VERSION "HIPBNYYYYYYYYYYYYYYYYYYYYYYYYYYYYYYYYYYYYY/4/%%%/4/'%**4YYY///"

NS_ :

BS_:

BU_: SpeedNode RFNode DisplayNode BMS MPPT

BO_ 3221225472 VECTOR__INDEPENDENT_SIG_MSG: 0 Vector__XXX
 SG_ State : 0|1@0+ (1,0) [0|0] "" Vector__XXX

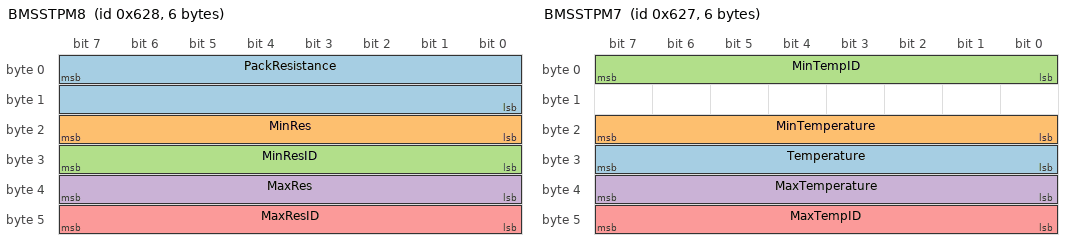
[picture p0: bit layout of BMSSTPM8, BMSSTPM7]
BO_ 1576 BMSSTPM8: 6 BMS
 SG_ PackResistance : 7|16@0+ (1,0) [0|0] "" Vector__XXX
 SG_ MinRes : 23|8@0+ (1,0) [0|0] "" Vector__XXX
 SG_ MinResID : 31|8@0+ (1,0) [0|0] "" Vector__XXX
 SG_ MaxRes : 39|8@0+ (1,0) [0|0] "" Vector__XXX
 SG_ MaxResID : 47|8@0+ (1,0) [0|0] "" Vector__XXX

BO_ 1575 BMSSTPM7: 6 BMS
 SG_ Temperature : 31|8@0+ (1,0) [0|0] "" Vector__XXX
 SG_ MinTemperature : 23|8@0+ (1,0) [0|0] "" Vector__XXX
 SG_ MinTempID : 7|8@0+ (1,0) [0|0] "" Vector__XXX
 SG_ MaxTemperature : 39|8@0+ (1,0) [0|0] "" Vector__XXX
 SG_ MaxTempID : 47|8@0+ (1,0) [0|0] "" Vector__XXX

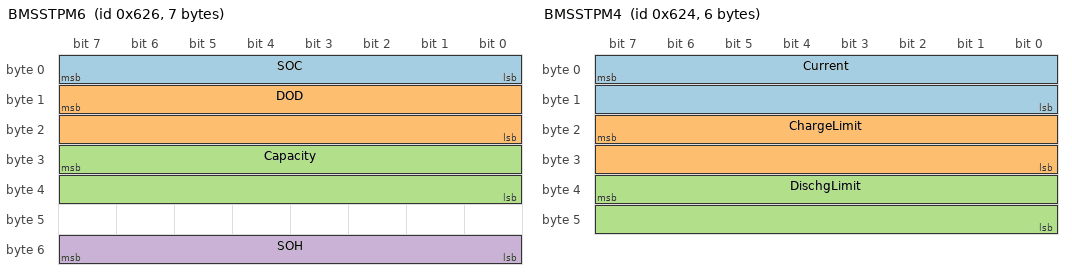
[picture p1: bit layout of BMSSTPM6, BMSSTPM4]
BO_ 1574 BMSSTPM6: 7 BMS
 SG_ SOC : 7|8@0+ (1,0) [0|0] "" Vector__XXX
 SG_ DOD : 15|16@0+ (1,0) [0|0] "" Vector__XXX
 SG_ Capacity : 31|16@0+ (1,0) [0|0] "" Vector__XXX
 SG_ SOH : 55|8@0+ (1,0) [0|0] "" Vector__XXX

BO_ 1573 BMSSTPM5: 8 BMS
 SG_ BattEnergyIn : 7|32@0+ (1,0) [0|0] "" Vector__XXX
 SG_ BattEnergyOut : 39|32@0+ (1,0) [0|0] "" Vector__XXX

BO_ 1572 BMSSTPM4: 6 BMS
 SG_ Current : 7|16@0+ (1,0) [0|0] "" Vector__XXX
 SG_ ChargeLimit : 23|16@0+ (1,0) [0|0] "" Vector__XXX
 SG_ DischgLimit : 39|16@0+ (1,0) [0|0] "" Vector__XXX

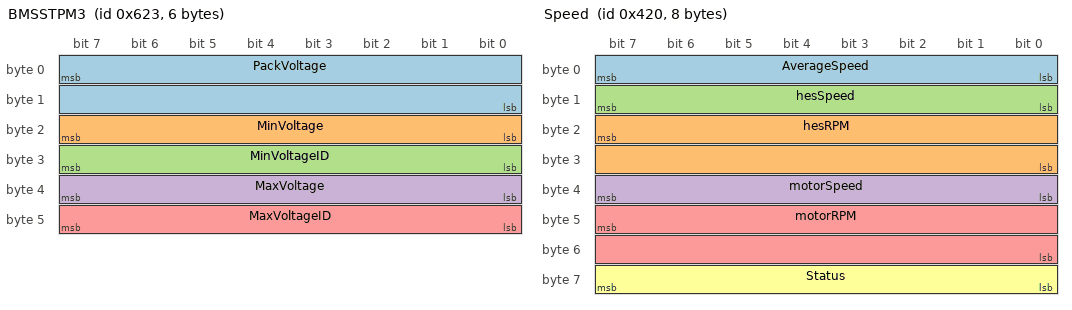
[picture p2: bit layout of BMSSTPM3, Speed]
BO_ 1571 BMSSTPM3: 6 BMS
 SG_ PackVoltage : 7|16@0+ (1,0) [0|0] "" Vector__XXX
 SG_ MinVoltage : 23|8@0+ (1,0) [0|0] "" Vector__XXX
 SG_ MinVoltageID : 31|8@0+ (1,0) [0|0] "" Vector__XXX
 SG_ MaxVoltage : 39|8@0+ (1,0) [0|0] "" Vector__XXX
 SG_ MaxVoltageID : 47|8@0+ (1,0) [0|0] "" Vector__XXX

BO_ 1570 BMSSTPM2: 7 BMS
 SG_ FaultState : 0|1@1+ (1,0) [0|0] "" Vector__XXX
 SG_ ContactorK1 : 1|1@1+ (1,0) [0|0] "" Vector__XXX
 SG_ ContactorK2 : 2|1@1+ (1,0) [0|0] "" Vector__XXX
 SG_ CANContactorRQ : 28|1@1+ (1,0) [0|0] "" Vector__XXX
 SG_ ContactorK3 : 3|1@1+ (1,0) [0|0] "" Vector__XXX
 SG_ RelayFault : 4|1@1+ (1,0) [0|0] "" Vector__XXX
 SG_ SrcPower : 24|1@1+ (1,0) [0|0] "" Vector__XXX
 SG_ LoadPwr : 25|1@1+ (1,0) [0|0] "" Vector__XXX
 SG_ InterlockTrip : 26|1@1+ (1,0) [0|0] "" Vector__XXX
 SG_ HWContactorRQ : 27|1@1+ (1,0) [0|0] "" Vector__XXX
 SG_ Timer : 15|16@0+ (1,0) [0|0] "" Vector__XXX
 SG_ HLIMSet : 29|1@1+ (1,0) [0|0] "" Vector__XXX
 SG_ LLIMSet : 30|1@1+ (1,0) [0|0] "" Vector__XXX
 SG_ FanOn : 31|1@1+ (1,0) [0|0] "" Vector__XXX
 SG_ StoredFaults : 39|8@0+ (1,0) [0|0] "" Vector__XXX
 SG_ PluginDriveOff : 40|1@1+ (1,0) [0|0] "" Vector__XXX
 SG_ InterlockTrip_Stored : 41|1@1+ (1,0) [0|0] "" Vector__XXX
 SG_ CommFaultBank : 42|1@1+ (1,0) [0|0] "" Vector__XXX
 SG_ CrgOvercurrent : 43|1@1+ (1,0) [0|0] "" Vector__XXX
 SG_ DischOvercurrent : 44|1@1+ (1,0) [0|0] "" Vector__XXX
 SG_ Overtemp : 45|1@1+ (1,0) [0|0] "" Vector__XXX
 SG_ Undervolt : 46|1@1+ (1,0) [0|0] "" Vector__XXX
 SG_ Overvolt : 47|1@1+ (1,0) [0|0] "" Vector__XXX
 SG_ LowVolt_Warn : 48|1@1+ (1,0) [0|0] "" Vector__XXX
 SG_ HiVolt_Warn : 49|1@1+ (1,0) [0|0] "" Vector__XXX
 SG_ Chrge_OC_Warn : 50|1@1+ (1,0) [0|0] "" Vector__XXX
 SG_ Discg_OC_Warn : 51|1@1+ (1,0) [0|0] "" Vector__XXX
 SG_ ColdTemp_Warn : 52|1@1+ (1,0) [0|0] "" Vector__XXX
 SG_ HotTemp_Warn : 53|1@1+ (1,0) [0|0] "" Vector__XXX
 SG_ lowSOH_Warn : 54|1@1+ (1,0) [0|0] "" Vector__XXX
 SG_ IsolatioFault_Warn : 55|1@1+ (1,0) [0|0] "" Vector__XXX

BO_ 1569 BMSSTPM1: 8 BMS
 SG_ Rev : 7|64@0+ (1,0) [0|0] "" Vector__XXX

BO_ 1056 Speed: 8 SpeedNode
 SG_ AverageSpeed : 7|8@0+ (1,0) [0|255] "kmph" Vector__XXX
 SG_ hesRPM : 23|16@0+ (1,0) [0|0] "" Vector__XXX
 SG_ hesSpeed : 15|8@0+ (1,0) [0|0] "" Vector__XXX
 SG_ motorSpeed : 39|8@0+ (1,0) [0|0] "" Vector__XXX
 SG_ motorRPM : 47|16@0+ (1,0) [0|0] "" Vector__XXX
 SG_ Status : 63|8@0+ (1,0) [0|0] "" Vector__XXX

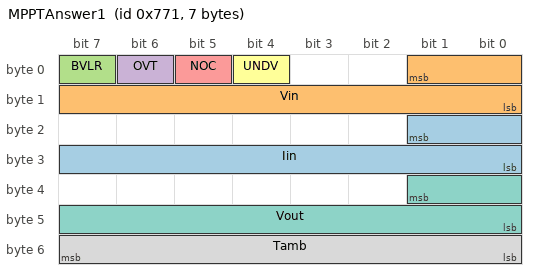
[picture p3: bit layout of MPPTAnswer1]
BO_ 1905 MPPTAnswer1: 7 MPPT
 SG_ Iin : 17|10@0+ (1,0) [0|0] "" Vector__XXX
 SG_ Vin : 1|10@0+ (1,0) [0|0] "" Vector__XXX
 SG_ BVLR : 7|1@1+ (1,0) [0|0] "" Vector__XXX
 SG_ OVT : 6|1@1+ (1,0) [0|0] "" Vector__XXX
 SG_ NOC : 5|1@1+ (1,0) [0|0] "" Vector__XXX
 SG_ UNDV : 4|1@1+ (1,0) [0|0] "" Vector__XXX
 SG_ Vout : 33|10@0+ (1,0) [0|0] "" Vector__XXX
 SG_ Tamb : 55|8@0+ (1,0) [0|0] "" Vector__XXX

BO_ 0 GPS: 8 RFNode

BO_ 1568 BMSSTPM0: 8 BMS
 SG_ ELITHION : 7|64@0+ (1,0) [0|0] "" Vector__XXX

CM_ BU_ SpeedNode "Terayza";
CM_ BU_ RFNode "Matt";
CM_ BU_ DisplayNode "Ben";
CM_ BO_ 3221225472 "This is a message for not used signals, created by Vector CANdb++ DBC OLE DB Provider.";
BA_DEF_ BO_  "GenMsgSendType" ENUM  "cyclic","spontaneous";
BA_DEF_ BO_  "GenMsgCycleTime" INT 2 50000;
BA_DEF_ BO_  "GenMsgAutoGenSnd" ENUM  "No","Yes";
BA_DEF_ BO_  "GenMsgAutoGenDsp" ENUM  "No","Yes";
BA_DEF_ SG_  "GenSigEnvVarType" ENUM  "int","float","undef";
BA_DEF_ BU_  "GenNodAutoGenSnd" ENUM  "No","Yes";
BA_DEF_ BU_  "GenNodAutoGenDsp" ENUM  "No","Yes";
BA_DEF_  "GenEnvVarEndingDsp" STRING ;
BA_DEF_  "GenEnvVarEndingSnd" STRING ;
BA_DEF_  "GenEnvVarPrefix" STRING ;
BA_DEF_DEF_  "GenMsgSendType" "spontaneous";
BA_DEF_DEF_  "GenMsgCycleTime" 100;
BA_DEF_DEF_  "GenMsgAutoGenSnd" "Yes";
BA_DEF_DEF_  "GenMsgAutoGenDsp" "Yes";
BA_DEF_DEF_  "GenSigEnvVarType" "undef";
BA_DEF_DEF_  "GenNodAutoGenSnd" "Yes";
BA_DEF_DEF_  "GenNodAutoGenDsp" "Yes";
BA_DEF_DEF_  "GenEnvVarEndingDsp" "Dsp";
BA_DEF_DEF_  "GenEnvVarEndingSnd" "Snd";
BA_DEF_DEF_  "GenEnvVarPrefix" "Env";
